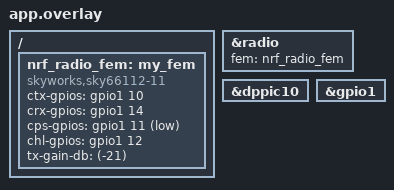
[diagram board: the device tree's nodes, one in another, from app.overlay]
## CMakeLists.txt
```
cmake_minimum_required(VERSION 3.20.0)
find_package(Zephyr REQUIRED HINTS $ENV{ZEPHYR_BASE})

project(neuton_ble_pull)

target_sources(app PRIVATE src/main.c)
```

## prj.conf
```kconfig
# Button and LED library
CONFIG_DK_LIBRARY=y

# Add logging
CONFIG_LOG=y

# Increase stack size for the main thread and System Workqueue
CONFIG_SYSTEM_WORKQUEUE_STACK_SIZE=2048
CONFIG_MAIN_STACK_SIZE=2048

# Bluetooth LE
CONFIG_BT=y
CONFIG_BT_PERIPHERAL=y
CONFIG_BT_DEVICE_NAME="NEUTON_PULL"
CONFIG_BT_MAX_CONN=1
CONFIG_BT_HCI_ACL_FLOW_CONTROL=y

# DLE and 2M PHY
CONFIG_BT_GATT_CLIENT=y
# CONFIG_BT_GAP_AUTO_UPDATE_CONN_PARAMS=n

CONFIG_BT_USER_PHY_UPDATE=y
CONFIG_BT_CTLR_PHY_2M=y

CONFIG_BT_USER_DATA_LEN_UPDATE=y
CONFIG_BT_CTLR_DATA_LENGTH_MAX=251
CONFIG_BT_BUF_ACL_TX_SIZE=502
CONFIG_BT_BUF_ACL_RX_SIZE=502
CONFIG_BT_L2CAP_TX_MTU=498
CONFIG_BT_L2CAP_DYNAMIC_CHANNEL=y
CONFIG_BT_CONN_TX_MAX=10
CONFIG_BT_BUF_EVT_RX_COUNT=11
CONFIG_BT_BUF_ACL_TX_COUNT=10
CONFIG_BT_BUF_ACL_TX_SIZE=502
CONFIG_BT_CTLR_SDC_MAX_CONN_EVENT_LEN_DEFAULT=4000000

CONFIG_BT_BUF_CMD_TX_COUNT=10

CONFIG_NRFX_GPPI=y
CONFIG_MPSL=y
CONFIG_MPSL_FEM=y
CONFIG_MPSL_FEM_SIMPLE_GPIO=y
CONFIG_GPIO=y

# If manual
# CONFIG_BT_CTLR_TX_PWR_ANTENNA=14

# Trying dynamic+let stack do work
CONFIG_BT_CTLR_ADVANCED_FEATURES=y
CONFIG_BT_CTLR_CONN_RSSI=y
CONFIG_BT_CTLR_TX_PWR_DYNAMIC_CONTROL=y
```

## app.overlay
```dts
/ {
    nrf_radio_fem: my_fem {
        compatible = "skyworks,sky66112-11", "generic-fem-two-ctrl-pins";
        ctx-gpios = <&gpio1 10 GPIO_ACTIVE_HIGH>; // LED1
        crx-gpios = <&gpio1 14 GPIO_ACTIVE_HIGH>; // LED3
        cps-gpios = <&gpio1 11 GPIO_ACTIVE_LOW>; // free
        chl-gpios = <&gpio1 12 GPIO_ACTIVE_HIGH>; // free
        tx-gain-db = < (-21) >; // Depends on VCC2 -> 3V,+21/20dBm | 1V8,+16dBm | 1V2,+13dBm. Driver defaults 22.
    }; // Try gain=bypass loss inverse approach when using hci pwr ctrl.
    //if using direct radio ctrl, have it be positive and just manually drive TXPOWER based on the table.
};

&radio {
    fem = <&nrf_radio_fem>;
};

&dppic10 {
    status = "okay";
};

// &ppib11 {
    //     status = "okay";
// };

&gpio1 {
    status = "okay";
};
```

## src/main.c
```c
/*
 * neuton_ble_pull
 * main.c
 * ble application, mocks some sensor data and sends it to le char.
 * includes a rx characteristic in some dev cfg is also needed.
 * uses dle, phy, conn param for bigger packets.
 * play w/ the connection params (or remove and use the commented config in prj.conf)
 * to get a connection situation that is best for your intended central.
 * auth: ddhd
 * SPDX-License-Identifier: LicenseRef-Nordic-5-Clause
 */

#include <dk_buttons_and_leds.h>
#include <zephyr/bluetooth/bluetooth.h>
#include <zephyr/bluetooth/conn.h>
#include <zephyr/bluetooth/gatt.h>
#include <zephyr/bluetooth/hci.h>
#include <zephyr/bluetooth/hci_vs.h>
#include <zephyr/bluetooth/uuid.h>
#include <zephyr/device.h>
#include <zephyr/devicetree.h>
#include <zephyr/kernel.h>
#include <zephyr/logging/log.h>
#include <zephyr/settings/settings.h>
#include <zephyr/sys/byteorder.h>
#include <zephyr/sys/printk.h>

#include <hal/nrf_gpio.h>
#include <zephyr/drivers/gpio.h>

#define RADIO_TX_MANUAL 0

#define GPIO1_NODE DT_NODELABEL(gpio1)
#define CPS_PIN 11
#define CHL_PIN 12
const struct device *gpio1_dev = DEVICE_DT_GET(GPIO1_NODE);

LOG_MODULE_REGISTER(neuton_pull_ble, LOG_LEVEL_INF);
#define DK_STATUS_LED DK_LED1
#define BLE_STATE_LED DK_LED2

#define SAMPLE_WINDOW 100 // 100 samples per chunk
#define SENS_SAMPLE_INTERVAL 10

// can also use zbus, or pass with work container w/ kernel work item.
struct sens_sample_msg
{
    uint8_t ip_dat[SAMPLE_WINDOW];
};
// 8 messages, 4-byte alignment
K_MSGQ_DEFINE(sens_msgq, sizeof(struct sens_sample_msg), 8, 4);

#define BLE_NOTIFY_INTERVAL K_MSEC(SENS_SAMPLE_INTERVAL *SAMPLE_WINDOW)
#define BLE_THREAD_STACK_SIZE 1024
#define BLE_THREAD_PRIORITY 5

// Declaration of custom GATT service and characteristics UUIDs
#define NEUTON_PULL_SERVICE_UUID BT_UUID_128_ENCODE(0x69e5204b, 0x8445, 0x5fca, 0xb332, 0xc13064b9dea2)
#define SENS_DAT_TX_CHARACTERISTIC_UUID BT_UUID_128_ENCODE(0x5E85012D, 0x7ea8, 0x4008, 0xb432, 0xb46096c049ba)
#define DEVC_CFG_RX_CHARACTERISTIC_UUID BT_UUID_128_ENCODE(0xDE70CF61, 0xd8ee, 0x4faf, 0x956b, 0xafb01c17d0be)

#define BT_UUID_NEUTON_PULL BT_UUID_DECLARE_128(NEUTON_PULL_SERVICE_UUID)
#define BT_UUID_SENS_DAT_TX BT_UUID_DECLARE_128(SENS_DAT_TX_CHARACTERISTIC_UUID)
#define BT_UUID_DEVC_CFG_RX BT_UUID_DECLARE_128(DEVC_CFG_RX_CHARACTERISTIC_UUID)

#define DEVICE_NAME CONFIG_BT_DEVICE_NAME // from prj.conf
#define DEVICE_NAME_LEN (sizeof(DEVICE_NAME) - 1)

volatile bool bypass_mode = false;

static const struct bt_le_adv_param *adv_param =
    BT_LE_ADV_PARAM((BT_LE_ADV_OPT_CONN | BT_LE_ADV_OPT_USE_IDENTITY), /* Connectable advertising and use
                                                                          identity address */
                    800,   /* Min Advertising Interval 500ms (800*0.625ms) 16383 max*/
                    801,   /* Max Advertising Interval 500.625ms (801*0.625ms) 16384 max*/
                    NULL); /* Set to NULL for undirected advertising */

static struct k_work adv_work;
static const struct bt_data ad[] = {
    BT_DATA_BYTES(BT_DATA_FLAGS, (BT_LE_AD_GENERAL | BT_LE_AD_NO_BREDR)),
    BT_DATA(BT_DATA_NAME_COMPLETE, DEVICE_NAME, DEVICE_NAME_LEN),
};

static void read_conn_rssi(uint16_t handle, int8_t *rssi)
{
    struct net_buf *buf, *rsp = NULL;
    struct bt_hci_cp_read_rssi *cp;
    struct bt_hci_rp_read_rssi *rp;

    int err;

    buf = bt_hci_cmd_alloc(K_FOREVER);
    if (!buf)
    {
        printk("Unable to allocate command buffer\n");
        return;
    }

    cp = net_buf_add(buf, sizeof(*cp));
    cp->handle = sys_cpu_to_le16(handle);

    err = bt_hci_cmd_send_sync(BT_HCI_OP_READ_RSSI, buf, &rsp);
    if (err)
    {
        printk("Read RSSI err: %d\n", err);
        return;
    }

    rp = (void *)rsp->data;
    *rssi = rp->rssi;

    net_buf_unref(rsp);
}

static const struct bt_data sd[] = {
    BT_DATA_BYTES(BT_DATA_UUID128_ALL, NEUTON_PULL_SERVICE_UUID),
};

void on_le_param_updated(struct bt_conn *conn, uint16_t interval, uint16_t latency, uint16_t timeout)
{
    double connection_interval = interval * 1.25; // in ms
    uint16_t supervision_timeout = timeout * 10;  // in ms
    LOG_INF("Connection parameters updated: interval %.2f ms, latency %d intervals, timeout %d ms", connection_interval,
            latency, supervision_timeout);
}

void on_le_phy_updated(struct bt_conn *conn, struct bt_conn_le_phy_info *param)
{
    // PHY Updated
    if (param->tx_phy == BT_CONN_LE_TX_POWER_PHY_1M)
    {
        LOG_INF("PHY updated. New PHY: 1M");
    }
    else if (param->tx_phy == BT_CONN_LE_TX_POWER_PHY_2M)
    {
        LOG_INF("PHY updated. New PHY: 2M");
    }

    // shouldnt happen
    else if (param->tx_phy == BT_CONN_LE_TX_POWER_PHY_CODED_S8)
    {
        LOG_INF("PHY updated. New PHY: Long Range");
    }
}

void on_le_data_len_updated(struct bt_conn *conn, struct bt_conn_le_data_len_info *info)
{
    uint16_t tx_len = info->tx_max_len;
    uint16_t tx_time = info->tx_max_time;
    uint16_t rx_len = info->rx_max_len;
    uint16_t rx_time = info->rx_max_time;
    LOG_INF("Data length updated. Length %d/%d bytes, time %d/%d us", tx_len, rx_len, tx_time, rx_time);
}

/*This function is called whenever the Client Characteristic Control Descriptor
(CCCD) has been changed by the GATT client, for each of the characteristics*/
static void on_cccd_changed(const struct bt_gatt_attr *attr, uint16_t value)
{
    ARG_UNUSED(attr);
    switch (value)
    {
    case BT_GATT_CCC_NOTIFY:
        break;
    case 0:
        break;
    default:
        LOG_ERR("Error, CCCD has been set to an invalid value");
    }
}

// fn called when dev cfg wr characteristic has been written to by a client
static ssize_t on_recv_cfg(struct bt_conn *conn, const struct bt_gatt_attr *attr, const void *buf, uint16_t len,
                           uint16_t offset, uint8_t flags)
{
    const uint8_t *buffer = buf;

    printk("Received cfg wr data, handle %d, conn %p, len %d, data: 0x", attr->handle, conn, len);
    for (uint8_t i = 0; i < len; i++)
    {
        printk("%02X", buffer[i]);
    }
    printk("\n");

    return len;
}

BT_GATT_SERVICE_DEFINE(neuton_pull, BT_GATT_PRIMARY_SERVICE(BT_UUID_NEUTON_PULL),
                       BT_GATT_CHARACTERISTIC(BT_UUID_SENS_DAT_TX, BT_GATT_CHRC_NOTIFY, BT_GATT_PERM_READ, NULL, NULL,
                                              NULL),
                       BT_GATT_CCC(on_cccd_changed, BT_GATT_PERM_READ | BT_GATT_PERM_WRITE),
                       BT_GATT_CHARACTERISTIC(BT_UUID_DEVC_CFG_RX, BT_GATT_CHRC_WRITE | BT_GATT_CHRC_WRITE_WITHOUT_RESP,
                                              BT_GATT_PERM_READ | BT_GATT_PERM_WRITE, NULL, on_recv_cfg, NULL), );

// BT globals and callbacks
struct bt_conn *m_connection = NULL;
static uint16_t m_conn_handle;

static struct bt_gatt_exchange_params exchange_params;
static void adv_work_handler(struct k_work *work)
{
    int err = bt_le_adv_start(adv_param, ad, ARRAY_SIZE(ad), sd, ARRAY_SIZE(sd));
    if (err)
    {
        LOG_INF("Advertising failed to start (err %d)", err);
        return;
    }

    LOG_INF("Advertising successfully started");
}

static void advertising_start(void)
{
    k_work_submit(&adv_work);
}

static void recycled_cb(void)
{
    LOG_INF("Connection object available from previous conn. Disconnect is "
            "complete!");
    advertising_start();
}

static void update_phy(struct bt_conn *conn)
{
    int err;
    const struct bt_conn_le_phy_param preferred_phy = {
        .options = BT_CONN_LE_PHY_OPT_NONE,
        .pref_rx_phy = BT_GAP_LE_PHY_2M,
        .pref_tx_phy = BT_GAP_LE_PHY_2M,
    };
    err = bt_conn_le_phy_update(conn, &preferred_phy);
    if (err)
    {
        LOG_ERR("bt_conn_le_phy_update() returned %d", err);
    }
}

static void update_data_length(struct bt_conn *conn)
{
    int err;
    struct bt_conn_le_data_len_param my_data_len = {
        .tx_max_len = CONFIG_BT_CTLR_DATA_LENGTH_MAX,
        .tx_max_time = BT_GAP_DATA_TIME_MAX,
    };
    err = bt_conn_le_data_len_update(m_connection, &my_data_len);
    if (err)
    {
        LOG_ERR("data_len_update failed (err %d)", err);
    }
}

static void exchange_func(struct bt_conn *conn, uint8_t att_err, struct bt_gatt_exchange_params *params)
{
    LOG_INF("MTU exchange %s", att_err == 0 ? "successful" : "failed");
    if (!att_err)
    {
        uint16_t payload_mtu = bt_gatt_get_mtu(conn) - 3; // 3 bytes used for Attribute headers.
        LOG_INF("New MTU: %d bytes", payload_mtu);
    }
}

static void update_mtu(struct bt_conn *conn)
{
    int err;
    exchange_params.func = exchange_func;

    err = bt_gatt_exchange_mtu(conn, &exchange_params);
    if (err)
    {
        LOG_ERR("bt_gatt_exchange_mtu failed (err %d)", err);
    }
}

static void connected(struct bt_conn *conn, uint8_t err)
{
    int ret;
    if (err)
    {
        LOG_WRN("Connection failed (err %u)", err);
        return;
    }
    m_connection = bt_conn_ref(conn);
    ret = bt_hci_get_conn_handle(m_connection, &m_conn_handle);
    LOG_INF("Connected");

    struct bt_conn_info info;
    err = bt_conn_get_info(m_connection, &info);
    if (err)
    {
        LOG_ERR("bt_conn_get_info() returned %d", err);
        return;
    }
    double connection_interval = info.le.interval * 1.25; // in ms
    uint16_t supervision_timeout = info.le.timeout * 10;  // in ms
    LOG_INF("Connection parameters: interval %.2f ms, latency %d intervals, timeout %d ms", connection_interval,
            info.le.latency, supervision_timeout);

    update_phy(m_connection);
    k_sleep(K_MSEC(1000)); // Delay added to avoid link layer collisions.
    update_data_length(m_connection);
    update_mtu(m_connection);

    dk_set_led_on(BLE_STATE_LED);
}

static void disconnected(struct bt_conn *conn, uint8_t reason)
{
    LOG_INF("Disconnected (reason %u)", reason);
    bt_conn_unref(m_connection);
    m_connection = NULL;
    dk_set_led_off(BLE_STATE_LED);
}

struct bt_conn_cb connection_callbacks = {
    .connected = connected,
    .disconnected = disconnected,
    .recycled = recycled_cb,
    .le_param_updated = on_le_param_updated,
    .le_phy_updated = on_le_phy_updated,
    .le_data_len_updated = on_le_data_len_updated,
};

static void ble_sens_report(struct bt_conn *conn, const uint8_t *data, uint16_t len)
{
    const struct bt_gatt_attr *attr = &neuton_pull.attrs[2];
    struct bt_gatt_notify_params params = {
        .uuid = BT_UUID_SENS_DAT_TX, .attr = attr, .data = data, .len = len, .func = NULL};

    if (bt_gatt_is_subscribed(conn, attr, BT_GATT_CCC_NOTIFY))
    {
        if (bt_gatt_notify_cb(conn, &params))
        {
            LOG_ERR("Error, unable to send notification");
        }
    }
    else
    {
        LOG_WRN("Warning, notification not enabled for sens dat characteristic");
    }
}

void ble_write_thread(void)
{
    struct sens_sample_msg msg;
    for (;;)
    {
        // wait until ip dat rdy
        k_msgq_get(&sens_msgq, &msg, K_FOREVER);
        // printk("BLE thread received data: 0x");
        // for (uint8_t i = 0; i < SAMPLE_WINDOW; i++)
        // {
        //     printk(" %02X", msg.ip_dat[i]);
        // }
        // printk("\n");

        if (m_connection) // if ble connection present
        {
            ble_sens_report(m_connection, &msg.ip_dat[0], SAMPLE_WINDOW);
        }
        else
        {
            LOG_INF("BLE Thread does not detect an active BLE connection");
        }

        k_sleep(K_MSEC(5000));
    }
}

//~~~~ SENS ~~~~//
#define SENS_THREAD_STACK_SIZE 1024
#define SENS_THREAD_PRIORITY 5
#define SENS_SAMPLE_INTERVAL_MS K_MSEC(SENS_SAMPLE_INTERVAL)

void sens_sample_thread(void)
{
    int err;
    uint8_t iter = 0;

    struct sens_sample_msg msg;

    for (;;)
    {
        msg.ip_dat[0] = iter++;
        for (uint8_t i = 1; i < SAMPLE_WINDOW; i++)
        {
            msg.ip_dat[i] = i;
            k_sleep(SENS_SAMPLE_INTERVAL_MS);
        }

        // LOG_INF("sens thread sent %d samples", SAMPLE_WINDOW);
        err = k_msgq_put(&sens_msgq, &msg, K_FOREVER);
        if (err != 0)
        {
            LOG_ERR("issue putting message into kmsgq in sens thread");
        }
        k_sleep(K_MSEC(10));
    }
}

// uses global bypass_mode
static void cfg_bypass_gpio(void)
{
    // cps active low in dts, chl active high.
    // cps=high for bypass, chl=high for high pwr tx
    if (bypass_mode)
    {
        gpio_pin_set(gpio1_dev, CPS_PIN, GPIO_OUTPUT_INACTIVE);
        gpio_pin_set(
            gpio1_dev, CHL_PIN,
            GPIO_OUTPUT_INACTIVE); // technically a dont care for bypass/nonbypass but illustrative for tx modes
    }
    else
    {
        gpio_pin_set(gpio1_dev, CPS_PIN, GPIO_OUTPUT_ACTIVE);
        gpio_pin_set(gpio1_dev, CHL_PIN, GPIO_OUTPUT_ACTIVE);
    }
}

// IDK if SDC messes with this so lets cache
volatile uint32_t txpower_cache;

// Manual TXPWR
static void enter_bypass_manual_radio_ctrl(void)
{
    bypass_mode = true;
    printk("ENTERING BYPASS, NEW TXPOWER=0x3F (+8dBm)\n");
    txpower_cache = NRF_RADIO->TXPOWER;
    NRF_RADIO->TXPOWER = 0x3F; // +8 dBm
    printk("NRF_RADIO->TXPOWER:0x%x\n", NRF_RADIO->TXPOWER);
    cfg_bypass_gpio();
}

static void exit_bypass_manual_radio_ctrl(void)
{
    bypass_mode = false;
    printk("LEAVING BYPASS, restoring cached TXPOWER 0x%x\n", txpower_cache);
    NRF_RADIO->TXPOWER = txpower_cache;
    printk("NRF_RADIO->TXPOWER:0x%x\n", NRF_RADIO->TXPOWER);
    cfg_bypass_gpio();
}

// Since my FEM bypass loss is -21, we can ask for -21 for 0dbm (PA on) or -13 for
// bypass (+8 dBm)
#if !(RADIO_TX_MANUAL)
#define BYPASS_OFF_21DBM -21
#define BYPASS_OFF_20DBM -22
#define BYPASS_OFF_19DBM -23
#define BYPASS_ON_8DBM -13
#define BYPASS_ON_7DBM -14
#define BYPASS_ON_6DBM -15
#else
//! DBG: SANITY CHECK. If you switch tx-gain-db in dts to be +21, you'll see it will be wrong.
#define FEM_PA_GAIN 21
#define BYPASS_OFF_21DBM 21
#define BYPASS_OFF_20DBM 20
#define BYPASS_OFF_19DBM 19
// if this works, then the ceiling for hci txpower cmds isn't capped by socdbm register max
#define BYPASS_ON_8DBM FEM_PA_GAIN + 8
#define BYPASS_ON_7DBM FEM_PA_GAIN + 7
#define BYPASS_ON_6DBM FEM_PA_GAIN + 6
#endif

// HCI TXPWR
/* The value you set is interpreted as the desired output power at the antenna,
and the stack will automatically adjust the SoC output power and FEM gain to
achieve the requested value as closely as possible.
The actual TX power reported back reflects the combined effect of the SoC and FEM*/

static void set_tx_power(uint8_t handle_type, uint16_t handle, int8_t tx_pwr_lvl)
{
    struct bt_hci_cp_vs_write_tx_power_level *cp;
    struct bt_hci_rp_vs_write_tx_power_level *rp;
    struct net_buf *buf, *rsp = NULL;
    int err;

    buf = bt_hci_cmd_alloc(K_FOREVER);
    if (!buf)
    {
        printk("Unable to allocate command buffer\n");
        return;
    }

    cp = net_buf_add(buf, sizeof(*cp));
    cp->handle = sys_cpu_to_le16(handle);
    cp->handle_type = handle_type;
    cp->tx_power_level = tx_pwr_lvl;

    err = bt_hci_cmd_send_sync(BT_HCI_OP_VS_WRITE_TX_POWER_LEVEL, buf, &rsp);
    if (err)
    {
        printk("Set Tx power err: %d\n", err);
        return;
    }

    rp = (void *)rsp->data;
    printk("Actual Tx Power: %d\n", rp->selected_tx_power);

    net_buf_unref(rsp);
}

static void get_tx_power(uint8_t handle_type, uint16_t handle, int8_t *tx_pwr_lvl)
{
    struct bt_hci_cp_vs_read_tx_power_level *cp;
    struct bt_hci_rp_vs_read_tx_power_level *rp;
    struct net_buf *buf, *rsp = NULL;
    int err;

    *tx_pwr_lvl = 0xFF;
    buf = bt_hci_cmd_alloc(K_FOREVER);
    if (!buf)
    {
        printk("Unable to allocate command buffer\n");
        return;
    }

    cp = net_buf_add(buf, sizeof(*cp));
    cp->handle = sys_cpu_to_le16(handle);
    cp->handle_type = handle_type;

    err = bt_hci_cmd_send_sync(BT_HCI_OP_VS_READ_TX_POWER_LEVEL, buf, &rsp);
    if (err)
    {
        printk("Read Tx power err: %d\n", err);
        return;
    }

    rp = (void *)rsp->data;
    *tx_pwr_lvl = rp->tx_power_level;

    net_buf_unref(rsp);
}

int main(void)
{
    int err;
    int blink = 0;
    int8_t txp_get = 0;

    err = dk_leds_init();
    if (err)
    {
        LOG_ERR("LEDs init failed (err %d)", err);
        return -1;
    }

    // Setting up Bluetooth
    err = bt_enable(NULL);
    if (err)
    {
        LOG_ERR("Bluetooth init failed (err %d)", err);
        return -1;
    }
    LOG_INF("Bluetooth initialized");
    if (IS_ENABLED(CONFIG_SETTINGS))
    {
        settings_load();
    }
    bt_conn_cb_register(&connection_callbacks);
    k_work_init(&adv_work, adv_work_handler);
    advertising_start();

    gpio_pin_configure(gpio1_dev, CPS_PIN, GPIO_OUTPUT);
    gpio_pin_configure(gpio1_dev, CHL_PIN, GPIO_OUTPUT);

    printk("STARTUP NRF_RADIO->TXPOWER:0x%x\n", NRF_RADIO->TXPOWER);
    // note: may need to audit RADIO_TXP_DEFAULT in hci_driver.c
    // I think we can drive this without CONFIG_BT_CTLR_TX_PWR_DYNAMIC_CONTROL though
    // bt_hci_cmd_send_sync(BT_HCI_OP_VS_WRITE_TX_POWER_LEVEL,buf, &rsp); is bounded
    // by SoC TXPOWER register, unless we flip the gain to bypass loss in the dts.

    k_msleep(100);

    printk("READING NRF_RADIO->TXPOWER FROM DTS+CONFIG AFTER STARTUP: 0x%x\n", NRF_RADIO->TXPOWER);

    // printk("Setting new base NRF_RADIO->TXPOWER: 0x18\n");
    // NRF_RADIO->TXPOWER = 0x18;
    // printk("NRF_RADIO->TXPOWER:0x%x\n",NRF_RADIO->TXPOWER);

    for (;;)
    {
        if (RADIO_TX_MANUAL)
        {
            enter_bypass_manual_radio_ctrl();

            dk_set_led(DK_STATUS_LED, (++blink) % 2);
            k_sleep(K_MSEC(2000));

            exit_bypass_manual_radio_ctrl();

            k_sleep(K_MSEC(15));
        }
        else
        {
            int8_t txp;
            if (bypass_mode)
            {
                printk("BYPASS MODE\n");
            }
            else
            {
                printk("NOT BYPASS MODE\n");
            }
            // Be smarter about this. If you exit bypass without compensating for what TXPWR is requested, you risk an unsafe combination.
            cfg_bypass_gpio(); 
            // You can handle this in conn cb, adv, or modulate based on read_conn_rssi.
            if (!m_connection)
            {
                txp = bypass_mode ? BYPASS_ON_8DBM : BYPASS_OFF_21DBM;
                printk("Set Tx power level to %d\n", txp);
                set_tx_power(BT_HCI_VS_LL_HANDLE_TYPE_ADV, 0, txp);
                k_sleep(K_MSEC(100));

                printk("Get Tx power level -> ");
                get_tx_power(BT_HCI_VS_LL_HANDLE_TYPE_ADV, 0, &txp_get);
                printk("TXP = %d\n", txp_get);
                k_sleep(K_SECONDS(5));
            }
            else
            {
                int8_t rssi = 0xFF;
                int8_t txp_adaptive;

                read_conn_rssi(m_conn_handle, &rssi);
                printk("Connected (%d) - RSSI = %d\n", m_conn_handle, rssi);
                if (rssi > -70)
                {
                    txp_adaptive = bypass_mode ? BYPASS_ON_6DBM : BYPASS_OFF_19DBM;
                }
                else if (rssi > -90)
                {
                    txp_adaptive = bypass_mode ? BYPASS_ON_7DBM : BYPASS_OFF_20DBM;
                }
                else
                {
                    txp_adaptive = bypass_mode ? BYPASS_ON_8DBM : BYPASS_OFF_21DBM;
                }
                printk("Adaptive Tx power selected = %d\n", txp_adaptive);
                set_tx_power(BT_HCI_VS_LL_HANDLE_TYPE_CONN, m_conn_handle, txp_adaptive);
                get_tx_power(BT_HCI_VS_LL_HANDLE_TYPE_CONN, m_conn_handle, &txp_get);
                printk("Connection (%d) TXP = %d\n", m_connection, txp_get);

                k_sleep(K_SECONDS(1));
            }
            printk("NRF_RADIO->TXPOWER:0x%x\n", NRF_RADIO->TXPOWER);
            k_sleep(K_MSEC(500));
            bypass_mode = !bypass_mode;
        }
    }
    return 0;
}

K_THREAD_DEFINE(sens_sample_thread_id, SENS_THREAD_STACK_SIZE, sens_sample_thread, NULL, NULL, NULL,
                SENS_THREAD_PRIORITY, 0, 0);
K_THREAD_DEFINE(ble_write_thread_id, BLE_THREAD_STACK_SIZE, ble_write_thread, NULL, NULL, NULL, BLE_THREAD_PRIORITY, 0,
                0);
```
